# RT584ZCM33 register map
Series: ARMv8-M Mainline; File version: 1.0
CPU: CM33 r0p0, little endian, MPU, no FPU, VTOR, 3 interrupt priority bits
Registers are 32-bit, read-write, reset 0x0 unless marked. A register's access mark holds for its fields unless they carry their own. Offsets are from the block's base; [hi:lo] are bit positions; {n}, {i} and the like mark numbered series.

## SYS_CTRL_Non-Secure — SYS_CTRL Non-Secure Register block
Base 0x40000000
Same registers: SYS_CTRL_Secure 0x50000000
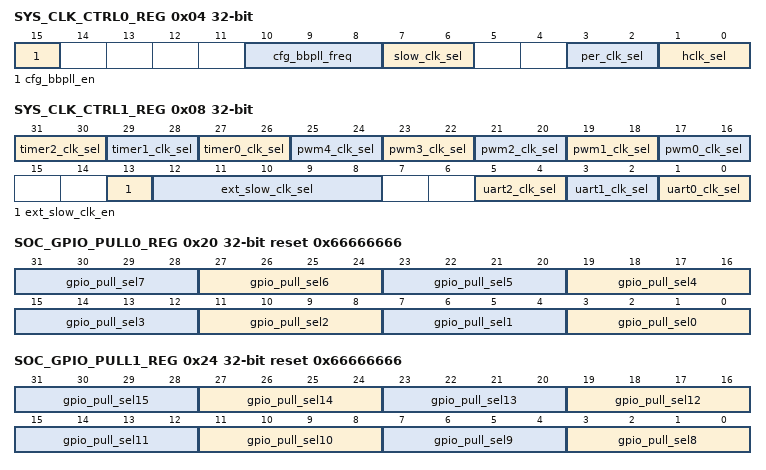
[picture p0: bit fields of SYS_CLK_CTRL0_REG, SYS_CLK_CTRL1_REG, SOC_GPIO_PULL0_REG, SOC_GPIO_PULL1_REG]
0x04 SYS_CLK_CTRL0_REG — sys clk ctrl0
  [15] cfg_bbpll_en — Baseband PLL enable 0: disabl 1: enable
    0=B_15_ITEM0 (disabl); 1=B_15_ITEM1 (enable)
  [10:8] cfg_bbpll_freq — Baseband PLL frequency 0: 48 MHz 1: 64 MHz 2: reserved 3: reserved 4: 24 MHz 5: 32 MHz 6: 36 MHz 7: 40 MHz
    0=B_8_to_10_ITEM0 (48 MHz); 1=B_8_to_10_ITEM1 (64 MHz); 2=B_8_to_10_ITEM2 (Not Used); 3=B_8_to_10_ITEM3 (Not Used); 4=B_8_to_10_ITEM4 (24 MHz); 5=B_8_to_10_ITEM5 (32 MHz); 6=B_8_to_10_ITEM6 (36 MHz); 7=B_8_to_10_ITEM7 (40 MHz)
  [7:6] slow_clk_sel — Slow clock selection 0: RCO 32K 1: XO 32K 2: Divided 32K (XTAL / 1024) 3: External 32K (From GPIO)
    0=B_6_to_7_ITEM0 (RCO 32K); 1=B_6_to_7_ITEM1 (XO 32K); 2=B_6_to_7_ITEM2 (Divided 32K (XTAL / 1024)); 3=B_6_to_7_ITEM3 (External 32K (From GPIO))
  [3:2] per_clk_sel — Peripheral clock selection 0: 32M 1: 32M 2: 16M 3: RCO1M
    0=B_2_to_3_ITEM0 (32M); 1=B_2_to_3_ITEM1 (32M); 2=B_2_to_3_ITEM2 (16M); 3=B_2_to_3_ITEM3 (RCO1M)
  [1:0] hclk_sel — HCLK selection 0: 32M 1: PLL clock (Depends on cfg_bbpll_freq) 2: 16M 3: RCO1M
    0=B_0_to_1_ITEM0 (32M); 1=B_0_to_1_ITEM1 (PLL clock (Depends on cfg_bbpll_freq)); 2=B_0_to_1_ITEM2 (16M); 3=B_0_to_1_ITEM3 (RCO1M)
0x08 SYS_CLK_CTRL1_REG — sys clk ctrl1
  [31:30] timer2_clk_sel — Timer2 clock selection 0 : Peripheral clock 1 : Peripheral clock 2 : RCO1M 3 : PMU_CLK
    0=B_30_to_31_ITEM0 (Peripheral clock); 1=B_30_to_31_ITEM1 (Peripheral clock); 2=B_30_to_31_ITEM2 (RCO1M); 3=B_30_to_31_ITEM3 (PMU_CLK)
  [29:28] timer1_clk_sel — Timer1 clock selection 0 : Peripheral clock 1 : Peripheral clock 2 : RCO1M 3 : PMU_CLK
    0=B_28_to_29_ITEM0 (Peripheral clock); 1=B_28_to_29_ITEM1 (Peripheral clock); 2=B_28_to_29_ITEM2 (RCO1M); 3=B_28_to_29_ITEM3 (PMU_CLK)
  [27:26] timer0_clk_sel — Timer0 clock selection 0 : Peripheral clock 1 : Peripheral clock 2 : RCO1M 3 : PMU_CLK
    0=B_26_to_27_ITEM0 (Peripheral clock); 1=B_26_to_27_ITEM1 (Peripheral clock); 2=B_26_to_27_ITEM2 (RCO1M); 3=B_26_to_27_ITEM3 (PMU_CLK)
  [2n+17:2n+16] pwm{n}_clk_sel (n=0..4) — PWM{n} clock selection 0 : MCU clock 1 : Peripheral clock 2 : RCO1M 3 : PMU_CLK
    0=B_{2n+16}_to_{2n+17}_ITEM0 (MCU clock); 1=B_{2n+16}_to_{2n+17}_ITEM1 (Peripheral clock); 2=B_{2n+16}_to_{2n+17}_ITEM2 (RCO1M); 3=B_{2n+16}_to_{2n+17}_ITEM3 (PMU_CLK)
  [13] ext_slow_clk_en — Enable external slow clock 0: disable 1: enable
    0=B_13_ITEM0 (disable); 1=B_13_ITEM1 (enable)
  [12:8] ext_slow_clk_sel — Select the related GPIOxx for the external slow clock. For example, 0x00 selects GPIO00 while 0x10 selects GPIO16.
    0=B_8_to_12 (Select the related GPIOxx for the external slow clock. For example, 0x00 selects GPIO00 while 0x10 selects GPIO16.)
  [5:4] uart2_clk_sel — UART2 clock selection 0 : Peripheral clock 1 : Peripheral clock 2 : RCO1M (It must be calibrated to 921.6K) 3 : RCO32K (It must be calibrated to 38.4K)
    0=B_4_to_5_ITEM0 (Peripheral clock); 1=B_4_to_5_ITEM1 (Peripheral clock); 2=B_4_to_5_ITEM2 (RCO1M (It must be calibrated to 921.6K)); 3=B_4_to_5_ITEM3 (RCO32K (It must be calibrated to 38.4K))
  [3:2] uart1_clk_sel — UART1 clock selection 0 : Peripheral clock 1 : Peripheral clock 2 : RCO1M (It must be calibrated to 921.6K) 3 : RCO32K (It must be calibrated to 38.4K)
    0=B_2_to_3_ITEM0 (Peripheral clock); 1=B_2_to_3_ITEM1 (Peripheral clock); 2=B_2_to_3_ITEM2 (RCO1M (It must be calibrated to 921.6K)); 3=B_2_to_3_ITEM3 (RCO32K (It must be calibrated to 38.4K))
  [1:0] uart0_clk_sel — UART0 clock selection 0 : Peripheral clock 1 : Peripheral clock 2 : RCO1M (It must be calibrated to 921.6K) 3 : RCO32K (It must be calibrated to 38.4K)
    0=B_0_to_1_ITEM0 (Peripheral clock); 1=B_0_to_1_ITEM1 (Peripheral clock); 2=B_0_to_1_ITEM2 (RCO1M (It must be calibrated to 921.6K)); 3=B_0_to_1_ITEM3 (RCO32K (It must be calibrated to 38.4K))
0x0C SYS_POWER_STATE_REG — sys power state
  [2:0] cfg_set_lowpower — Combined with MCU WFI/WFE commands to enter different low-power states. Before executing WFI/WFE commands, MCU shall set this register accordingly. 0: Normal mode. MCU just enter WFI/WFE. 1: Sleep mode. 2: Deepsleep mode. 4: Deep Powerdown mode.
    0=B_0_to_2 (Combined with MCU WFI/WFE commands to enter different low-power states. Before executing WFI/WFE commands, MCU shall set this register accordingly. 0: Normal mode. MCU just enter WFI/WFE. 1: Sleep mode. 2: Deepsleep mode. 4: Deep Powerdown mode.)
0x20 SOC_GPIO_PULL0_REG reset 0x66666666 — soc gpio pull0
  [4n+3:4n] gpio_pull_sel{n} (n=0..7) — GPIO{n} pull select 0: no pull 1: 10K pull down 2: 100K pull down 3: 1M pull down 4: no pull 5: 10k pull up 6: 100K pull up 7: 1M pull up oth: nouse
    0=B_{4n}_to_{4n+3}_ITEM0 (no pull); 1=B_{4n}_to_{4n+3}_ITEM1 (10K pull down); 2=B_{4n}_to_{4n+3}_ITEM2 (100K pull down); 3=B_{4n}_to_{4n+3}_ITEM3 (1M pull down); 4=B_{4n}_to_{4n+3}_ITEM4 (no pull); 5=B_{4n}_to_{4n+3}_ITEM5 (10k pull up); 6=B_{4n}_to_{4n+3}_ITEM6 (100K pull up); 7=B_{4n}_to_{4n+3}_ITEM7 (1M pull up); {v}=B_{4n}_to_{4n+3}_ITEM{v} (nouse) (v=8..15)
0x24 SOC_GPIO_PULL1_REG reset 0x66666666 — soc gpio pull1
  [4n-29:4n-32] gpio_pull_sel{n} (n=8..15) — GPIO{n} pull select 0: no pull 1: 10K pull down 2: 100K pull down 3: 1M pull down 4: no pull 5: 10k pull up 6: 100K pull up 7: 1M pull up oth: nouse
    0=B_{4n-32}_to_{4n-29}_ITEM0 (no pull); 1=B_{4n-32}_to_{4n-29}_ITEM1 (10K pull down); 2=B_{4n-32}_to_{4n-29}_ITEM2 (100K pull down); 3=B_{4n-32}_to_{4n-29}_ITEM3 (1M pull down); 4=B_{4n-32}_to_{4n-29}_ITEM4 (no pull); 5=B_{4n-32}_to_{4n-29}_ITEM5 (10k pull up); 6=B_{4n-32}_to_{4n-29}_ITEM6 (100K pull up); 7=B_{4n-32}_to_{4n-29}_ITEM7 (1M pull up); {v}=B_{4n-32}_to_{4n-29}_ITEM{v} (nouse) (v=8..15)
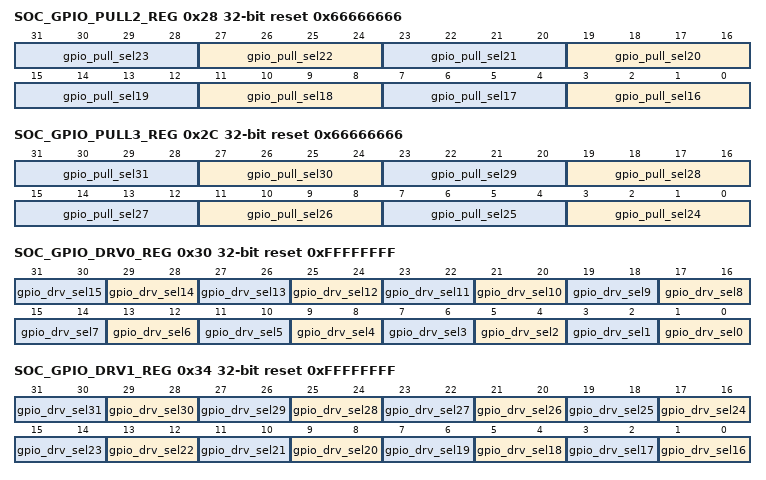
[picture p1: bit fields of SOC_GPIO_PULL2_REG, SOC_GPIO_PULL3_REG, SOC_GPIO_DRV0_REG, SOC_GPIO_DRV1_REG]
0x28 SOC_GPIO_PULL2_REG reset 0x66666666 — soc gpio pull2
  [4n-61:4n-64] gpio_pull_sel{n} (n=16..23) — GPIO{n} pull select 0: no pull 1: 10K pull down 2: 100K pull down 3: 1M pull down 4: no pull 5: 10k pull up 6: 100K pull up 7: 1M pull up oth: nouse
    0=B_{4n-64}_to_{4n-61}_ITEM0 (no pull); 1=B_{4n-64}_to_{4n-61}_ITEM1 (10K pull down); 2=B_{4n-64}_to_{4n-61}_ITEM2 (100K pull down); 3=B_{4n-64}_to_{4n-61}_ITEM3 (1M pull down); 4=B_{4n-64}_to_{4n-61}_ITEM4 (no pull); 5=B_{4n-64}_to_{4n-61}_ITEM5 (10k pull up); 6=B_{4n-64}_to_{4n-61}_ITEM6 (100K pull up); 7=B_{4n-64}_to_{4n-61}_ITEM7 (1M pull up); {v}=B_{4n-64}_to_{4n-61}_ITEM{v} (nouse) (v=8..15)
0x2C SOC_GPIO_PULL3_REG reset 0x66666666 — soc gpio pull3
  [4n-93:4n-96] gpio_pull_sel{n} (n=24..31) — GPIO{n} pull select 0: no pull 1: 10K pull down 2: 100K pull down 3: 1M pull down 4: no pull 5: 10k pull up 6: 100K pull up 7: 1M pull up oth: nouse
    0=B_{4n-96}_to_{4n-93}_ITEM0 (no pull); 1=B_{4n-96}_to_{4n-93}_ITEM1 (10K pull down); 2=B_{4n-96}_to_{4n-93}_ITEM2 (100K pull down); 3=B_{4n-96}_to_{4n-93}_ITEM3 (1M pull down); 4=B_{4n-96}_to_{4n-93}_ITEM4 (no pull); 5=B_{4n-96}_to_{4n-93}_ITEM5 (10k pull up); 6=B_{4n-96}_to_{4n-93}_ITEM6 (100K pull up); 7=B_{4n-96}_to_{4n-93}_ITEM7 (1M pull up); {v}=B_{4n-96}_to_{4n-93}_ITEM{v} (nouse) (v=8..15)
0x30 SOC_GPIO_DRV0_REG reset 0xFFFFFFFF — soc gpio drv0
  [2n+1:2n] gpio_drv_sel{n} (n=0..15) — GPIO{n} driving selection 0: driving strength 0 (weakest) 1: driving strength 1 2: driving strength 2 3: driving strength 3 (strongest)
    0=B_{2n}_to_{2n+1}_ITEM0 (driving strength 0 (weakest)); 1=B_{2n}_to_{2n+1}_ITEM1 (driving strength 1); 2=B_{2n}_to_{2n+1}_ITEM2 (driving strength 2); 3=B_{2n}_to_{2n+1}_ITEM3 (driving strength 3 (strongest))
0x34 SOC_GPIO_DRV1_REG reset 0xFFFFFFFF — soc gpio drv1
  [2n-31:2n-32] gpio_drv_sel{n} (n=16..31) — GPIO{n} driving selection 0: driving strength 0 (weakest) 1: driving strength 1 2: driving strength 2 3: driving strength 3 (strongest)
    0=B_{2n-32}_to_{2n-31}_ITEM0 (driving strength 0 (weakest)); 1=B_{2n-32}_to_{2n-31}_ITEM1 (driving strength 1); 2=B_{2n-32}_to_{2n-31}_ITEM2 (driving strength 2); 3=B_{2n-32}_to_{2n-31}_ITEM3 (driving strength 3 (strongest))
0x38 SOC_GPIO_EN_OD_REG — GPIOx open-drain enable 0: disabled 1: enabled
0x3C SOC_GPIO_EN_SCHMITT_REG — GPIOx input Schmitt Trigger enable 0: disabled 1: enabled
0x40 SOC_GPIO_EN_FILTER_REG — GPIOx input filter enable 0: disabled 1: enabled
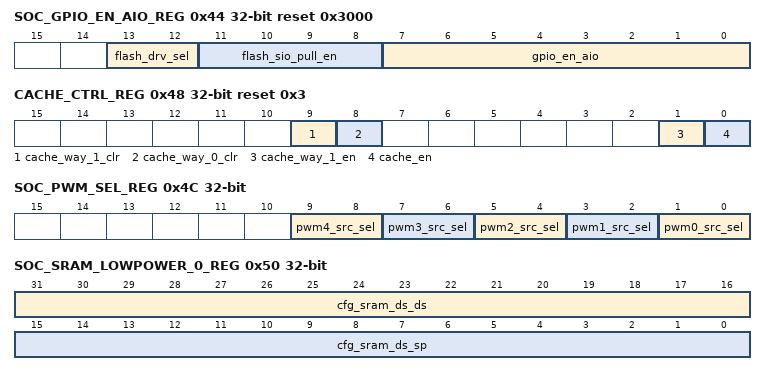
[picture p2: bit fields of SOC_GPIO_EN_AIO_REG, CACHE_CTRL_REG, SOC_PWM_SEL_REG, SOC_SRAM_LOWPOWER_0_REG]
0x44 SOC_GPIO_EN_AIO_REG reset 0x3000 — soc gpio en aio
  [13:12] flash_drv_sel — Flash PAD driving selection 0: driving strength 0 (weakest) 1: driving strength 1 2: driving strength 2 3: driving strength 3 (strongest)
    0=B_12_to_13_ITEM0 (driving strength 0 (weakest)); 1=B_12_to_13_ITEM1 (driving strength 1); 2=B_12_to_13_ITEM2 (driving strength 2); 3=B_12_to_13_ITEM3 (driving strength 3 (strongest))
  [11:8] flash_sio_pull_en — Flash SIOx pull-high enable 0: no pull 1: pull high
    0=B_8_to_11 (Flash SIOx pull-high enable 0: no pull 1: pull high)
  [7:0] gpio_en_aio — AIOx enable 0: disabled 1: enabled
    0=B_0_to_7 (AIOx enable 0: disabled 1: enabled)
0x48 CACHE_CTRL_REG reset 0x3 — cache ctrl
  [9] cache_way_1_clr wo — clear way 1 cache
    0=B_9 (clear way 1 cache)
  [8] cache_way_0_clr wo — clear way 0 cache
    0=B_8 (clear way 0 cache)
  [1] cache_way_1_en — Cache way select 0: 1-way cache 1: 2-way cache
    0=B_1_ITEM0 (1-way cache); 1=B_1_ITEM1 (2-way cache)
  [0] cache_en — Cache enable 0: Cache Disable 1: Cache Enable
    0=B_0_ITEM0 (Cache Disable); 1=B_0_ITEM1 (Cache Enable)
0x4C SOC_PWM_SEL_REG — soc pwm sel
  [2n+1:2n] pwm{n}_src_sel (n=0..4) — PWM{n} output source select. 0: From PWM{n} 1: From Timer0 2: From Timer1 3: From Timer2
    0=B_{2n}_to_{2n+1}_ITEM0 (From PWM{n}); 1=B_{2n}_to_{2n+1}_ITEM1 (From Timer0); 2=B_{2n}_to_{2n+1}_ITEM2 (From Timer1); 3=B_{2n}_to_{2n+1}_ITEM3 (From Timer2)
0x50 SOC_SRAM_LOWPOWER_0_REG — soc sram lowpower 0
  [31:16] cfg_sram_ds_ds — Set 1b to the individual bit to set SRAM in data retention mode when System is in Deepsleep mode. [0] : RAM0 (0x30000000-0x30007FFF) [1] : RAM1 (0x30008000-0x3000FFFF) [2] : RAM2 (0x30010000-0x30017FFF) [3] : RAM3 (0x30018000-0x3001FFFF) [4] : RAM4 (0x30020000-0x30027FFF) [5] : RAM5 (0x30028000-0x3002BFFF) [6] : RAM6 (0x3002C000-0x3002FFFF) [12:7] : Reserved [13] : ROM [14] : Cache RAM [15] : Crypto RAM
  [15:0] cfg_sram_ds_sp — Set 1b to the individual bit to set SRAM in data retention mode when System is in Sleep mode. [0] : RAM0 (0x30000000-0x30007FFF) [1] : RAM1 (0x30008000-0x3000FFFF) [2] : RAM2 (0x30010000-0x30017FFF) [3] : RAM3 (0x30018000-0x3001FFFF) [4] : RAM4 (0x30020000-0x30027FFF) [5] : RAM5 (0x30028000-0x3002BFFF) [6] : RAM6 (0x3002C000-0x3002FFFF) [12:7] : Reserved [13] : ROM [14] : Cache RAM [15] : Crypto RAM
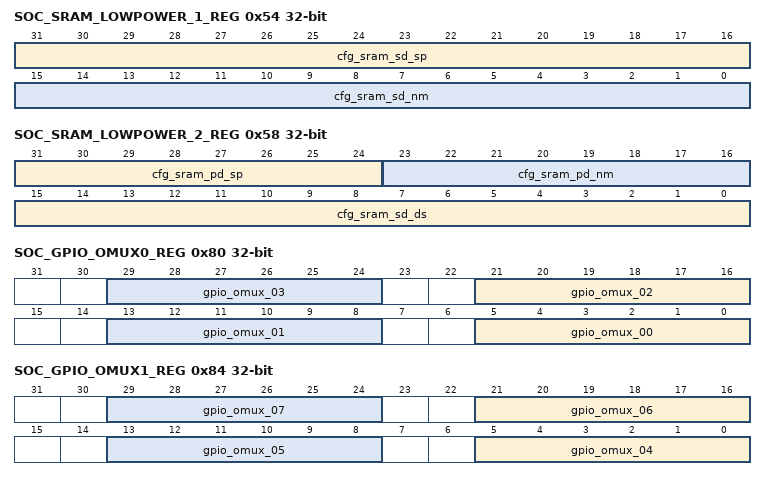
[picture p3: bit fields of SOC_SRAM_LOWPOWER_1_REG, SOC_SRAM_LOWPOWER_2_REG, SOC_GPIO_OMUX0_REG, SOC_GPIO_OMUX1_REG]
0x54 SOC_SRAM_LOWPOWER_1_REG — soc sram lowpower 1
  [31:16] cfg_sram_sd_sp — Set 1b to the individual bit to set SRAM in Shutdown mode when System is in Sleep mode. [0] : RAM0 (0x30000000-0x30007FFF) [1] : RAM1 (0x30008000-0x3000FFFF) [2] : RAM2 (0x30010000-0x30017FFF) [3] : RAM3 (0x30018000-0x3001FFFF) [4] : RAM4 (0x30020000-0x30027FFF) [5] : RAM5 (0x30028000-0x3002BFFF) [6] : RAM6 (0x3002C000-0x3002FFFF) [7] : Reserved [8] : CM0p0 (0x30040000-0x30047FFF) [9] : CM0p1 (0x30048000-0x3004FFFF) [10] : CM0p2 (0x30050000-0x30057FFF) [11:12]: Reserved [13] : ROM [14] : Cache RAM [15] : Crypto RAM
  [15:0] cfg_sram_sd_nm — Set 1b to the individual bit to set SRAM in Shutdown mode when System is in Normal mode. [0] : RAM0 (0x30000000-0x30007FFF) [1] : RAM1 (0x30008000-0x3000FFFF) [2] : RAM2 (0x30010000-0x30017FFF) [3] : RAM3 (0x30018000-0x3001FFFF) [4] : RAM4 (0x30020000-0x30027FFF) [5] : RAM5 (0x30028000-0x3002BFFF) [6] : RAM6 (0x3002C000-0x3002FFFF) [7] : Reserved [8] : CM0p0 (0x30040000-0x30047FFF) [9] : CM0p1 (0x30048000-0x3004FFFF) [10] : CM0p2 (0x30050000-0x30057FFF) [11:12]: Reserved [13] : ROM [14] : Cache RAM [15] : Crypto RAM
0x58 SOC_SRAM_LOWPOWER_2_REG — soc sram lowpower 2
  [31:24] cfg_sram_pd_sp — Set 1b to the individual bit to set SRAM in Powerdown mode when System is in Sleep mode. [0] : RAM0 (0x30000000-0x30007FFF) : RAM1 (0x30008000-0x3000FFFF) [1] : RAM2 (0x30010000-0x30017FFF) : RAM3 (0x30018000-0x3001FFFF) [2] : RAM4 (0x30020000-0x30027FFF) [3] : RAM5 (0x30028000-0x3002BFFF) [4] : RAM6 (0x3002C000-0x3002FFFF) [7:5] : Reserved
    0=B_24_to_31 (Set 1b to the individual bit to set SRAM in Powerdown mode when System is in Sleep mode. [0] : RAM0 (0x30000000-0x30007FFF) : RAM1 (0x30008000-0x3000FFFF) [1] : RAM2 (0x30010000-0x30017FFF) : RAM3 (0x30018000-0x3001FFFF) [2] : RAM4 (0x30020000-0x30027FFF) [3] : RAM5 (0x30028000-0x3002BFFF) [4] : RAM6 (0x3002C000-0x3002FFFF) [7:5] : Reserved)
  [23:16] cfg_sram_pd_nm — Set 1b to the individual bit to set SRAM in Powerdown mode when System is in Normal mode. Once a SRAM is configured to be powered down in Normal mode, it will be also powered down in other modes. [0] : RAM0 (0x30000000-0x30007FFF) : RAM1 (0x30008000-0x3000FFFF) [1] : RAM2 (0x30010000-0x30017FFF) : RAM3 (0x30018000-0x3001FFFF) [2] : RAM4 (0x30020000-0x30027FFF) [3] : RAM5 (0x30028000-0x3002BFFF) [4] : RAM6 (0x3002C000-0x3002FFFF) [7:5] : Reserved
    0=B_16_to_23 (Set 1b to the individual bit to set SRAM in Powerdown mode when System is in Normal mode. Once a SRAM is configured to be powered down in Normal mode, it will be also powered down in other modes. [0] : RAM0 (0x30000000-0x30007FFF) : RAM1 (0x30008000-0x3000FFFF) [1] : RAM2 (0x30010000-0x30017FFF) : RAM3 (0x30018000-0x3001FFFF) [2] : RAM4 (0x30020000-0x30027FFF) [3] : RAM5 (0x30028000-0x3002BFFF) [4] : RAM6 (0x3002C000-0x3002FFFF) [7:5] : Reserved)
  [15:0] cfg_sram_sd_ds — Set 1b to the individual bit to set SRAM in Shutdown mode when System is in Deepsleep mode. [0] : RAM0 (0x30000000-0x30007FFF) [1] : RAM1 (0x30008000-0x3000FFFF) [2] : RAM2 (0x30010000-0x30017FFF) [3] : RAM3 (0x30018000-0x3001FFFF) [4] : RAM4 (0x30020000-0x30027FFF) [5] : RAM5 (0x30028000-0x3002BFFF) [6] : RAM6 (0x3002C000-0x3002FFFF) [7] : Reserved [8] : CM0p0 (0x30040000-0x30047FFF) [9] : CM0p1 (0x30048000-0x3004FFFF) [10] : CM0p2 (0x30050000-0x30057FFF) [11:12]: Reserved [13] : ROM [14] : Cache RAM [15] : Crypto RAM
0x5C SOC_SRAM_LOWPOWER_3_REG reset 0x2F80000 — soc sram lowpower 3
  [7:0] cfg_sram_pd_ds — Set 1b to the individual bit to set SRAM in Powerdown mode when System is in Deepsleep mode. [0] : RAM0 (0x30000000-0x30007FFF) : RAM1 (0x30008000-0x3000FFFF) [1] : RAM2 (0x30010000-0x30017FFF) : RAM3 (0x30018000-0x3001FFFF) [2] : RAM4 (0x30020000-0x30027FFF) [3] : RAM5 (0x30028000-0x3002BFFF) [4] : RAM6 (0x3002C000-0x3002FFFF) [7:5] : Reserved
    0=B_0_to_7 (Set 1b to the individual bit to set SRAM in Powerdown mode when System is in Deepsleep mode. [0] : RAM0 (0x30000000-0x30007FFF) : RAM1 (0x30008000-0x3000FFFF) [1] : RAM2 (0x30010000-0x30017FFF) : RAM3 (0x30018000-0x3001FFFF) [2] : RAM4 (0x30020000-0x30027FFF) [3] : RAM5 (0x30028000-0x3002BFFF) [4] : RAM6 (0x3002C000-0x3002FFFF) [7:5] : Reserved)
0x80 SOC_GPIO_OMUX0_REG — soc gpio omux0
  [8n+5:8n] gpio_omux_{n:02} (n=0..3) — Refer to the table GPIO_OMUX.
    0=B_{8n}_to_{8n+5} (Refer to the table GPIO_OMUX.)
0x84 SOC_GPIO_OMUX1_REG — soc gpio omux1
  [8n-27:8n-32] gpio_omux_{n:02} (n=4..7) — Refer to the table GPIO_OMUX.
    0=B_{8n-32}_to_{8n-27} (Refer to the table GPIO_OMUX.)
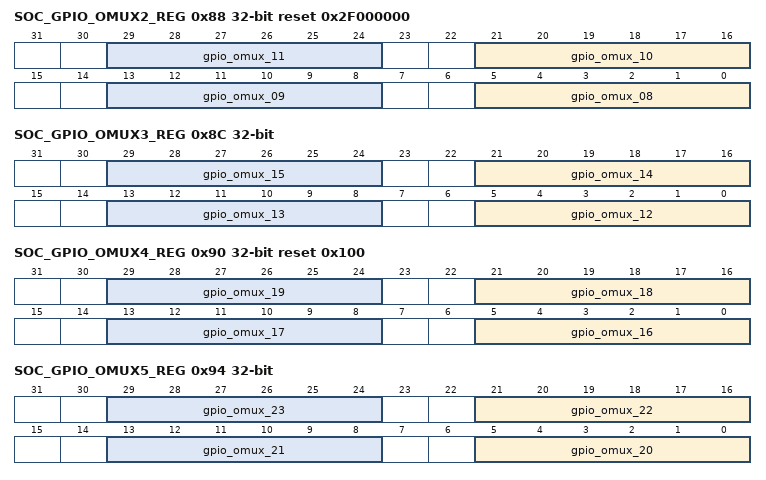
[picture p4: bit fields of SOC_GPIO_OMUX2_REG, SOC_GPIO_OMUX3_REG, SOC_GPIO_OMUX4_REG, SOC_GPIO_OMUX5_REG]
0x88 SOC_GPIO_OMUX2_REG reset 0x2F000000 — soc gpio omux2
  [8n-59:8n-64] gpio_omux_{n:02} (n=8..11) — Refer to the table GPIO_OMUX.
    0=B_{8n-64}_to_{8n-59} (Refer to the table GPIO_OMUX.)
0x8C SOC_GPIO_OMUX3_REG — soc gpio omux3
  [8n-91:8n-96] gpio_omux_{n} (n=12..15) — Refer to the table GPIO_OMUX.
    0=B_{8n-96}_to_{8n-91} (Refer to the table GPIO_OMUX.)
0x90 SOC_GPIO_OMUX4_REG reset 0x100 — soc gpio omux4
  [8n-123:8n-128] gpio_omux_{n} (n=16..19) — Refer to the table GPIO_OMUX.
    0=B_{8n-128}_to_{8n-123} (Refer to the table GPIO_OMUX.)
0x94 SOC_GPIO_OMUX5_REG — soc gpio omux5
  [8n-155:8n-160] gpio_omux_{n} (n=20..23) — Refer to the table GPIO_OMUX.
    0=B_{8n-160}_to_{8n-155} (Refer to the table GPIO_OMUX.)
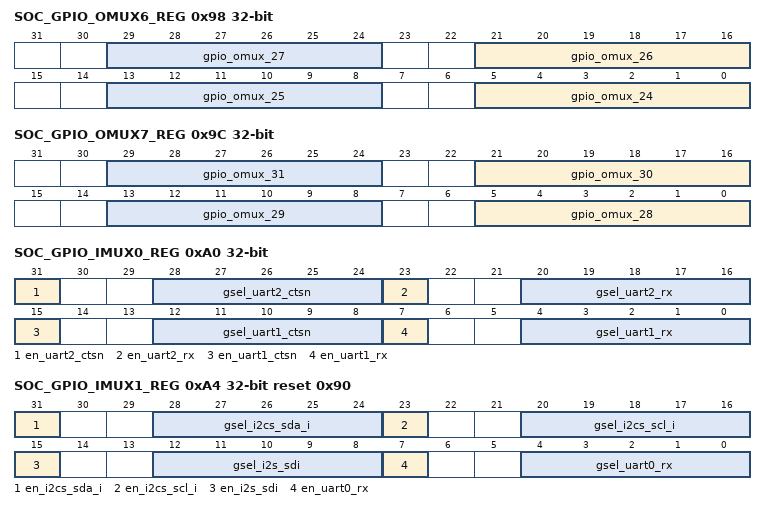
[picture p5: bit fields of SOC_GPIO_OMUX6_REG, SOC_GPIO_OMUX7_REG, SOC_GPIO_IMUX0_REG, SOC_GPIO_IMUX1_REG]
0x98 SOC_GPIO_OMUX6_REG — soc gpio omux6
  [8n-187:8n-192] gpio_omux_{n} (n=24..27) — Refer to the table GPIO_OMUX.
    0=B_{8n-192}_to_{8n-187} (Refer to the table GPIO_OMUX.)
0x9C SOC_GPIO_OMUX7_REG — soc gpio omux7
  [8n-219:8n-224] gpio_omux_{n} (n=28..31) — Refer to the table GPIO_OMUX.
    0=B_{8n-224}_to_{8n-219} (Refer to the table GPIO_OMUX.)
0xA0 SOC_GPIO_IMUX0_REG — soc gpio imux0
  [31] en_uart2_ctsn — Enable UART2_CTSN input.
    0=B_31 (Enable UART2_CTSN input.)
  [28:24] gsel_uart2_ctsn — Select the related GPIOxx input for UART2_CTSN.
    0=B_24_to_28 (Select the related GPIOxx input for UART2_CTSN.)
  [23] en_uart2_rx — Enable UART2_RX input.
    0=B_23 (Enable UART2_RX input.)
  [20:16] gsel_uart2_rx — Select the related GPIOxx input for UART2_RX.
    0=B_16_to_20 (Select the related GPIOxx input for UART2_RX.)
  [15] en_uart1_ctsn — Enable UART1_CTSN input.
    0=B_15 (Enable UART1_CTSN input.)
  [12:8] gsel_uart1_ctsn — Select the related GPIOxx input for UART1_CTSN.
    0=B_8_to_12 (Select the related GPIOxx input for UART1_CTSN.)
  [7] en_uart1_rx — Enable UART1_RX input.
    0=B_7 (Enable UART1_RX input.)
  [4:0] gsel_uart1_rx — Select the related GPIOxx input for UART1_RX.
    0=B_0_to_4 (Select the related GPIOxx input for UART1_RX.)
0xA4 SOC_GPIO_IMUX1_REG reset 0x90 — soc gpio imux1
  [31] en_i2cs_sda_i — Enable I2CS_SDA_in input.
    0=B_31 (Enable I2CS_SDA_in input.)
  [28:24] gsel_i2cs_sda_i — Select the related GPIOxx input for I2CS_SDA_in.
    0=B_24_to_28 (Select the related GPIOxx input for I2CS_SDA_in.)
  [23] en_i2cs_scl_i — Enable I2CS_SCL_in input.
    0=B_23 (Enable I2CS_SCL_in input.)
  [20:16] gsel_i2cs_scl_i — Select the related GPIOxx input for I2CS_SCL_in.
    0=B_16_to_20 (Select the related GPIOxx input for I2CS_SCL_in.)
  [15] en_i2s_sdi — Enable I2S_SDI input.
    0=B_15 (Enable I2S_SDI input.)
  [12:8] gsel_i2s_sdi — Select the related GPIOxx input for I2S_SDI.
    0=B_8_to_12 (Select the related GPIOxx input for I2S_SDI.)
  [7] en_uart0_rx — Enable UART0_RX input.
    0=B_7 (Enable UART0_RX input.)
  [4:0] gsel_uart0_rx — Select the related GPIOxx input for UART0_RX.
    0=B_0_to_4 (Select the related GPIOxx input for UART0_RX.)
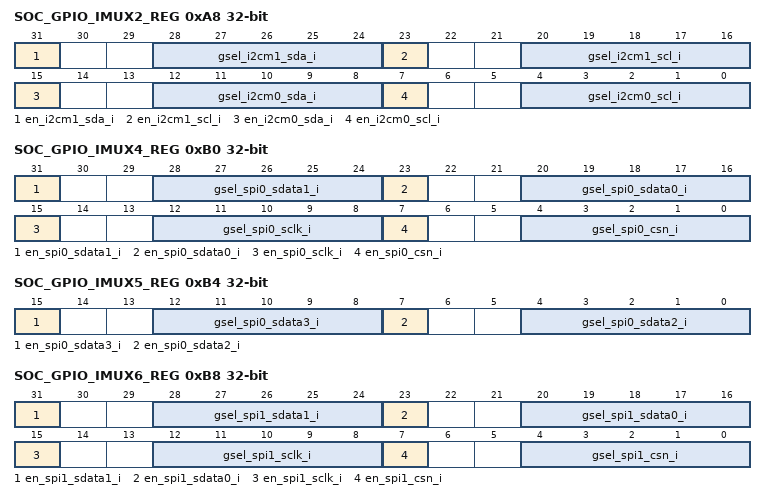
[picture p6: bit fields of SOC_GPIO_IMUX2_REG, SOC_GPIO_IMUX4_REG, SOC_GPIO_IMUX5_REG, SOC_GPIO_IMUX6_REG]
0xA8 SOC_GPIO_IMUX2_REG — soc gpio imux2
  [31] en_i2cm1_sda_i — Enable I2CM1_SDA_in input.
    0=B_31 (Enable I2CM1_SDA_in input.)
  [28:24] gsel_i2cm1_sda_i — Select the related GPIOxx input for I2CM1_SDA_in.
    0=B_24_to_28 (Select the related GPIOxx input for I2CM1_SDA_in.)
  [23] en_i2cm1_scl_i — Enable I2CM1_SCL_in input.
    0=B_23 (Enable I2CM1_SCL_in input.)
  [20:16] gsel_i2cm1_scl_i — Select the related GPIOxx input for I2CM1_SCL_in.
    0=B_16_to_20 (Select the related GPIOxx input for I2CM1_SCL_in.)
  [15] en_i2cm0_sda_i — Enable I2CM0_SDA_in input.
    0=B_15 (Enable I2CM0_SDA_in input.)
  [12:8] gsel_i2cm0_sda_i — Select the related GPIOxx input for I2CM0_SDA_in.
    0=B_8_to_12 (Select the related GPIOxx input for I2CM0_SDA_in.)
  [7] en_i2cm0_scl_i — Enable I2CM0_SCL_in input.
    0=B_7 (Enable I2CM0_SCL_in input.)
  [4:0] gsel_i2cm0_scl_i — Select the related GPIOxx input for I2CM0_SCL_in.
    0=B_0_to_4 (Select the related GPIOxx input for I2CM0_SCL_in.)
0xB0 SOC_GPIO_IMUX4_REG — soc gpio imux4
  [31] en_spi0_sdata1_i — Enable SPI0_SDATA_in[1] input.
    0=B_31 (Enable SPI0_SDATA_in[1] input.)
  [28:24] gsel_spi0_sdata1_i — Select the related GPIOxx input forSPI0_SDATA_in[1].
    0=B_24_to_28 (Select the related GPIOxx input forSPI0_SDATA_in[1].)
  [23] en_spi0_sdata0_i — Enable SPI0_SDATA_in[0] input.
    0=B_23 (Enable SPI0_SDATA_in[0] input.)
  [20:16] gsel_spi0_sdata0_i — Select the related GPIOxx input for SPI0_SDATA_in[0].
    0=B_16_to_20 (Select the related GPIOxx input for SPI0_SDATA_in[0].)
  [15] en_spi0_sclk_i — Enable SPI0_SCLK_in input.
    0=B_15 (Enable SPI0_SCLK_in input.)
  [12:8] gsel_spi0_sclk_i — Select the related GPIOxx input for SPI0_SCLK_in.
    0=B_8_to_12 (Select the related GPIOxx input for SPI0_SCLK_in.)
  [7] en_spi0_csn_i — Enable SPI0_CSN_in input.
    0=B_7 (Enable SPI0_CSN_in input.)
  [4:0] gsel_spi0_csn_i — Select the related GPIOxx input for SPI0_CSN_in.
    0=B_0_to_4 (Select the related GPIOxx input for SPI0_CSN_in.)
0xB4 SOC_GPIO_IMUX5_REG — soc gpio imux5
  [15] en_spi0_sdata3_i — Enable SPI0_SDATA_in[3] input.
    0=B_15 (Enable SPI0_SDATA_in[3] input.)
  [12:8] gsel_spi0_sdata3_i — Select the related GPIOxx input forSPI0_SDATA_in[3].
    0=B_8_to_12 (Select the related GPIOxx input forSPI0_SDATA_in[3].)
  [7] en_spi0_sdata2_i — Enable SPI0_SDATA_in[2] input.
    0=B_7 (Enable SPI0_SDATA_in[2] input.)
  [4:0] gsel_spi0_sdata2_i — Select the related GPIOxx input for SPI0_SDATA_in[2].
    0=B_0_to_4 (Select the related GPIOxx input for SPI0_SDATA_in[2].)
0xB8 SOC_GPIO_IMUX6_REG — soc gpio imux6
  [31] en_spi1_sdata1_i — Enable SPI1_SDATA_in[1] input.
    0=B_31 (Enable SPI1_SDATA_in[1] input.)
  [28:24] gsel_spi1_sdata1_i — Select the related GPIOxx input forSPI1_SDATA_in[1].
    0=B_24_to_28 (Select the related GPIOxx input forSPI1_SDATA_in[1].)
  [23] en_spi1_sdata0_i — Enable SPI1_SDATA_in[0] input.
    0=B_23 (Enable SPI1_SDATA_in[0] input.)
  [20:16] gsel_spi1_sdata0_i — Select the related GPIOxx input for SPI1_SDATA_in[0].
    0=B_16_to_20 (Select the related GPIOxx input for SPI1_SDATA_in[0].)
  [15] en_spi1_sclk_i — Enable SPI1_SCLK_in input.
    0=B_15 (Enable SPI1_SCLK_in input.)
  [12:8] gsel_spi1_sclk_i — Select the related GPIOxx input for SPI1_SCLK_in.
    0=B_8_to_12 (Select the related GPIOxx input for SPI1_SCLK_in.)
  [7] en_spi1_csn_i — Enable SPI1_CSN_in input.
    0=B_7 (Enable SPI1_CSN_in input.)
  [4:0] gsel_spi1_csn_i — Select the related GPIOxx input for SPI1_CSN_in.
    0=B_0_to_4 (Select the related GPIOxx input for SPI1_CSN_in.)
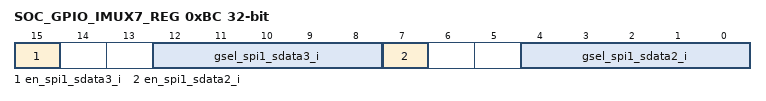
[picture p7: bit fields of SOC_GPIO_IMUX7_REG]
0xBC SOC_GPIO_IMUX7_REG — soc gpio imux7
  [15] en_spi1_sdata3_i — Enable SPI1_SDATA_in[3] input.
    0=B_15 (Enable SPI1_SDATA_in[3] input.)
  [12:8] gsel_spi1_sdata3_i — Select the related GPIOxx input forSPI1_SDATA_in[3].
    0=B_8_to_12 (Select the related GPIOxx input forSPI1_SDATA_in[3].)
  [7] en_spi1_sdata2_i — Enable SPI1_SDATA_in[2] input.
    0=B_7 (Enable SPI1_SDATA_in[2] input.)
  [4:0] gsel_spi1_sdata2_i — Select the related GPIOxx input for SPI1_SDATA_in[2].
    0=B_0_to_4 (Select the related GPIOxx input for SPI1_SDATA_in[2].)
